# DSP_MMU register map
Vendor: Texas Instruments
Peripheral module from a debugger description file (folder omap4430).
Registers are 32-bit, read-only, reset 0x0 unless marked. A register's access mark holds for its fields unless they carry their own. Offsets are as the file gives them; lines under a group give offsets from that group; [hi:lo] are bit positions; {n}, {i} and the like mark numbered series; 'fields as' and 'values as' point back to an identical list; <NAME> marks a mode.

## DSP_MMU
0x00 MMU_REVISION reset not defined — This register contains the IP revision code
  [31:0] REVISION — IP Revision
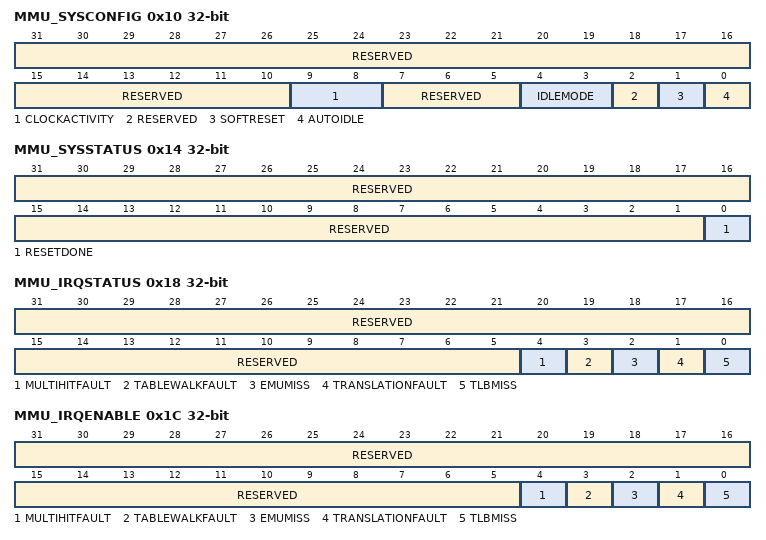
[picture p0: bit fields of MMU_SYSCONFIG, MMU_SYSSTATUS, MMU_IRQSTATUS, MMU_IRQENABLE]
0x10 MMU_SYSCONFIG access per field — This register controls the various parameters of the L3 interconnect interface
  [31:10] RESERVED ro — Write 0's for future compatibility Reads returns 0
  [9:8] CLOCKACTIVITY ro — Clock activity during wake-up mode 00 Functional and Interconnect clocks can be switched off
  [7:5] RESERVED ro — Write 0's for future compatibility Reads returns 0
  [4:3] IDLEMODE rw
    0=Force-idle. An idle request is acknowledged unconditionally; 1=No-idle. An idle request is never acknowledged; 2=Smart-idle. Acknowledgement to an idle request is given based on the internal activity of the module; 3=reserved do not use
  [2] RESERVED ro — Write 0's for future compatibility Reads returns 0
  [1] SOFTRESET rw — Software reset. This bit is automatically reset by the hardware. During reads, it always return 0
    0=SOFTRESET_0_r (always return 0); 0=SOFTRESET_0_w (no functional effect); 1=SOFTRESET_1_w (The module is reset); 1=SOFTRESET_1_r (never happens)
  [0] AUTOIDLE rw — Internal interconnect clock gating strategy
    0=interconnect clock is free-running; 1=Automatic interconnect clock gating strategy is applied, based on the interconnect interface activity
0x14 MMU_SYSSTATUS (reset mask 0xFFFFFFFE) — This register provides status information about the module, excluding the interrupt status information
  [31:1] RESERVED — Reads returns 0
  [0] RESETDONE — Internal reset monitoring
    0=RESETDONE_0_r (Internal module reset in on-going); 1=RESETDONE_1_r (Reset completed)
0x18 MMU_IRQSTATUS access not given — This interrupt status register regroups all the status of the module internal events that can generate an interrupt.
  [31:5] RESERVED ro — Write 0's for future compatibility read returns 0
  [4] MULTIHITFAULT — Error due to multiple matches in the TLB (access RW W1toClr)
    0=MULTIHITFAULT_0_r (MultiHitFault false); 0=MULTIHITFAULT_0_w (MultiHitFault status bit unchanged); 1=MULTIHITFAULT_1_w (MultiHitFault status bit is reset); 1=MULTIHITFAULT_1_r (MultiHitFault is true ('pending'))
  [3] TABLEWALKFAULT — Error response received during a Table Walk (access RW W1toClr)
    0=TABLEWALKFAULT_0_r (TableWalkFault false); 0=TABLEWALKFAULT_0_w (TableWalkFault status bit unchanged); 1=TABLEWALKFAULT_1_w (TableWalkFault status bit is reset); 1=TABLEWALKFAULT_1_r (TableWalkFault is true ('pending'))
  [2] EMUMISS — Unrecoverable TLB miss during debug (hardware TWL disabled) (access RW W1toClr)
    0=EMUMISS_0_r (EMUMiss false); 0=EMUMISS_0_w (EMUMiss status bit unchanged); 1=EMUMISS_1_w (EMUMiss status bit is reset); 1=EMUMISS_1_r (EMUMiss is true ('pending'))
  [1] TRANSLATIONFAULT — Invalid descriptor in translation tables (translation fault) (access RW W1toClr)
    0=TRANSLATIONFAULT_0_r (TranslationFault false); 0=TRANSLATIONFAULT_0_w (TranslationFault status bit unchanged); 1=TRANSLATIONFAULT_1_w (TranslationFault status bit is reset); 1=TRANSLATIONFAULT_1_r (TranslationFault is true ('pending'))
  [0] TLBMISS — Unrecoverable TLB miss (hardware TWL disabled) (access RW W1toClr)
    0=TLBMISS_0_r (TLBMiss false); 0=TLBMISS_0_w (TLBMiss status bit unchanged); 1=TLBMISS_1_w (TLBMiss status bit is reset); 1=TLBMISS_1_r (TLBMiss is true ('pending'))
0x1C MMU_IRQENABLE access per field — The interrupt enable register allows to mask/unmask the module internal sources of interrupt, on a event-by-event basis.
  [31:5] RESERVED ro — Write 0's for future compatibility Read returns 0
  [4] MULTIHITFAULT rw — Error due to multiple matches in the TLB
    0=MultiHitFault is masked; 1=MultiHitFault event generates an interrupt if occurs
  [3] TABLEWALKFAULT rw — Error response received during a Table Walk
    0=TableWalkFault is masked; 1=TableWalkFault event generates an interrupt if occurs
  [2] EMUMISS rw — Unrecoverable TLB miss during debug (hardware TWL disabled)
    0=EMUMiss interrupt is masked; 1=EMUMiss event generates an interrupt when it occurs
  [1] TRANSLATIONFAULT rw — Invalid descriptor in translation tables (translation fault)
    0=TranslationFault is masked; 1=TranslationFault event generates an interrupt if occurs
  [0] TLBMISS rw — Unrecoverable TLB miss (hardware TWL disabled)
    0=TLBMiss interrupt is masked; 1=TLBMiss event generates an interrupt when if occurs
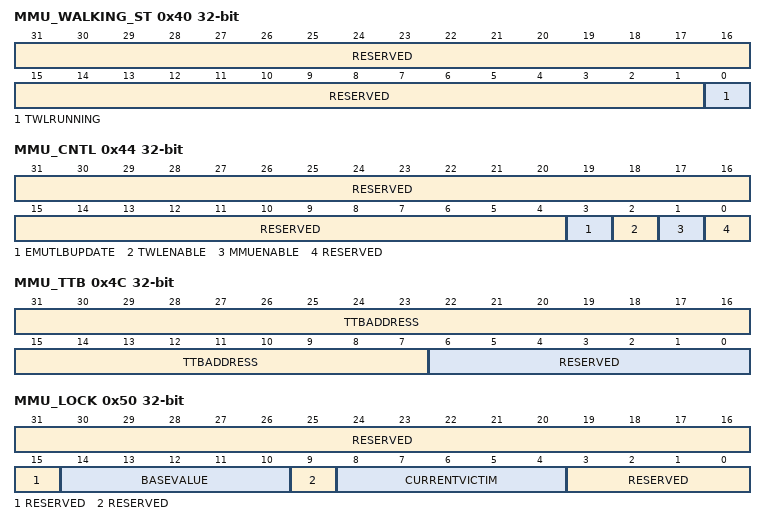
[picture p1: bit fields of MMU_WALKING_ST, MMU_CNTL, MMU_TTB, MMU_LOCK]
0x40 MMU_WALKING_ST — This register provides status information about the table walking logic
  [31:1] RESERVED — Reads return 0
  [0] TWLRUNNING — Table Walking Logic is running
    0=TWLRUNNING_0_r (TWL Completed); 1=TWLRUNNING_1_r
0x44 MMU_CNTL access per field — This register programs the MMU features
  [31:4] RESERVED ro — Write 0's for future compatibility Reads return 0
  [3] EMUTLBUPDATE rw — Enable TLB update on emulator table walk
    0=Emulator TLB update disabled; 1=Emulator TLB update enabled
  [2] TWLENABLE rw — Table Walking Logic enable
    0=TWL disabled; 1=TWL enabled
  [1] MMUENABLE rw
    0=MMU disabled; 1=MMU enabled
  [0] RESERVED ro — Write 0's for future compatibility Reads return 0
0x48 MMU_FAULT_AD — This register contains the virtual address that generated the interrupt
  [31:0] FAULTADDRESS — Virtual address of the access that generated a fault
0x4C MMU_TTB access per field — This register contains the Translation Table Base address
  [31:7] TTBADDRESS rw — Translation Table Base Address
  [6:0] RESERVED ro — Write 0's for future compatibility Reads retiurn 0
0x50 MMU_LOCK access per field — This register locks some of the TLB entries
  [31:15] RESERVED ro — Write 0's for future compatibility Reads return 0
  [14:10] BASEVALUE rw — Locked entries base value
  [9] RESERVED ro — Write 0's for future compatibility Read returns 0
  [8:4] CURRENTVICTIM rw — Current entry to be updated either by the TWL or by the software Write value : TLB entry to be updated by software, Read value : TLB entry that will be updated by table walk logic
  [3:0] RESERVED ro — Write 0's for future compatibility Reads return 0
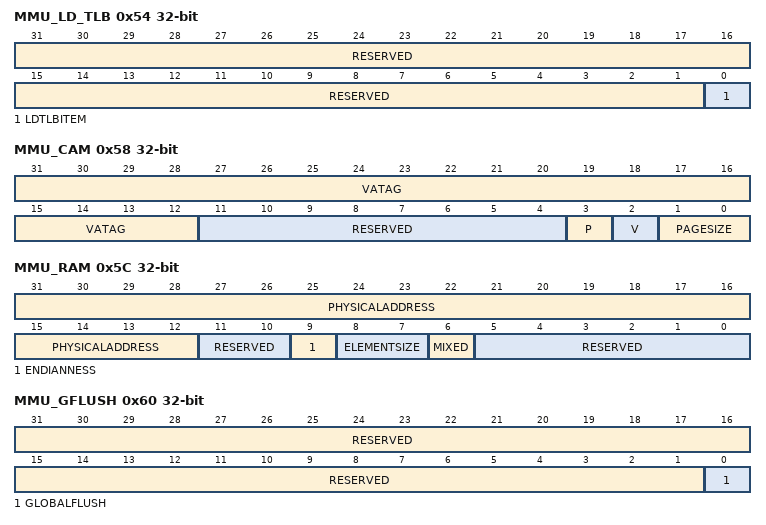
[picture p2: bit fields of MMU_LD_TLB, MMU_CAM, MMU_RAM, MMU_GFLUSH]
0x54 MMU_LD_TLB rw — This register loads a TLB entry (CAM+RAM)
  [31:1] RESERVED — Write 0's for future compatibility Reads return 0
  [0] LDTLBITEM — Write (load) data in the TLB
    0=LDTLBITEM_0_r (always return 0); 0=LDTLBITEM_0_w (no functional effect); 1=LDTLBITEM_1_w (load TLB data); 1=LDTLBITEM_1_r (never happens)
0x58 MMU_CAM access per field — This register holds a CAM entry
  [31:12] VATAG rw — Virtual address tag
  [11:4] RESERVED ro — Write 0's for future compatibility Reads return 0
  [3] P rw — Preserved bit
    0=TLB entry may be flushed; 1=TLB entry is protected against flush
  [2] V rw — Valid bit
    0=TLB entry is invalid; 1=TLB entry is valid
  [1:0] PAGESIZE rw
    0=Section (1MB); 1=Large page (64KB); 2=Small page (4KB); 3=Supersection (16MB)
0x5C MMU_RAM access per field — This register holds a RAM entry
  [31:12] PHYSICALADDRESS rw — Physical address of the page
  [11:10] RESERVED ro — Write 0's for future compatibility Reads return 0
  [9] ENDIANNESS rw — Endianness of the page
    0=Little Endian; 1=Big endian
  [8:7] ELEMENTSIZE rw — Element size of the page (8, 16, 32, no translation)
    0=8-bits; 1=16-bits; 2=32-bits; 3=No translation
  [6] MIXED rw — Mixed page attribute (use CPU element size)
    0=Use TLB element size; 1=Use CPU element size
  [5:0] RESERVED ro — Write 0's for future compatibility Reads return 0
0x60 MMU_GFLUSH rw — This register flushes all the non-protected TLB entries
  [31:1] RESERVED — Write 0's for future compatibility Reads return 0
  [0] GLOBALFLUSH — Flush all the non-protected TLB entries when set
    0=GLOBALFLUSH_0_r (always return 0); 0=GLOBALFLUSH_0_w (no functional effect); 1=GLOBALFLUSH_1_w (flush all the non-protected TLB entries); 1=GLOBALFLUSH_1_r (never happens)
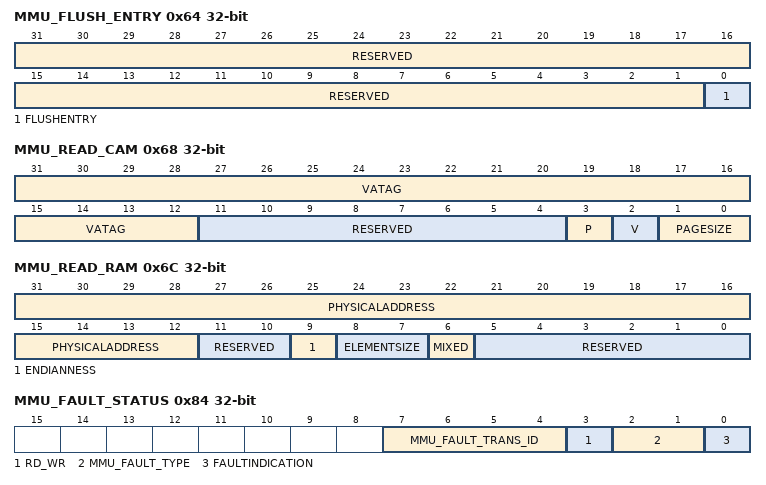
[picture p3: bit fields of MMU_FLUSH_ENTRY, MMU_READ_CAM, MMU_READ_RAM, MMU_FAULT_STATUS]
0x64 MMU_FLUSH_ENTRY rw — This register flushes the entry pointed to by the CAM virtual address
  [31:1] RESERVED — Write 0's for future compatibility Reads return 0
  [0] FLUSHENTRY — Flush the TLB entry pointed by the virtual address (VATag) inMMU_CAM register, even if this entry is set protected
    0=FLUSHENTRY_0_r (always return 0); 0=FLUSHENTRY_0_w (no functional effect); 1=FLUSHENTRY_1_w (flush all the TLB entries specified by the CAM register); 1=FLUSHENTRY_1_r (never happens)
0x68 MMU_READ_CAM — This register reads CAM data from a CAM entry
  [31:12] VATAG — Virtual address tag
  [11:4] RESERVED — Reads return 0
  [3] P — Preserved bit
    0=P_0_r (TLB entry may be flushed); 1=P_1_r (TLB entry is protected against flush)
  [2] V — Valid bit
    0=V_0_r (TLB entry is invalid); 1=V_1_r (TLB entry is valid)
  [1:0] PAGESIZE
    0=PAGESIZE_0_r (Section (1MB)); 1=PAGESIZE_1_r (Large page (64KB)); 2=PAGESIZE_2_r (Small page (4KB)); 3=PAGESIZE_3_r (Supersection (16MB))
0x6C MMU_READ_RAM — This register reads RAM data from a RAM entry
  [31:12] PHYSICALADDRESS — Physical address of the page
  [11:10] RESERVED — Reads return 0
  [9] ENDIANNESS — Endianness of the page
    0=ENDIANNESS_0_r (Little Endian); 1=ENDIANNESS_1_r (Big endian)
  [8:7] ELEMENTSIZE — Element size of the page (8, 16, 32, no translation)
    0=ELEMENTSIZE_0_r (8-bits); 1=ELEMENTSIZE_1_r (16-bits); 2=ELEMENTSIZE_2_r (32-bits); 3=ELEMENTSIZE_3_r (No translation)
  [6] MIXED — Mixed page attribute (use CPU element size)
    0=MIXED_0_r (Use TLB element size); 1=MIXED_1_r (Use CPU element size)
  [5:0] RESERVED — Reads return 0
0x70 MMU_EMU_FAULT_AD — This register contains the last virtual address of a fault caused by the debugger
  [31:0] EMUFAULTADDRESS — Virtual address of the last emulator access that generated a fault
0x80 MMU_FAULT_PC — Capture first fault PC value, controlled by[0] FAULTINDICATION. Notes: The address value is captured at [31:0] EMUFAULTADDRESS. Data-Read-access : corresponding PC. Data-write-access : not perfect accuracy due to Posted-write. All this description is valid only for the DSP MMU. The Cortex-M3 L2 MMU always reads zero from this register.
  [31:0] PC — CPU program counter value where cause MMU fault
0x84 MMU_FAULT_STATUS access not given
  [7:4] MMU_FAULT_TRANS_ID ro — Master ID who cause a faultRead 0x9 to 0xF: reserved (for both Cortex-M3 MMU and DSP MMU) .
    0=MMU_FAULT_TRANS_ID_0_r (posted writes out of shared cache for Cortex-M3 MMU / eDMA read port 1 for DSP MMU); 1=MMU_FAULT_TRANS_ID_1_r (Cortex-M3 video and display control processor I/D bus access for Cortex-M3 MMU / eDMA read port 2 for DSP MMU); 2=MMU_FAULT_TRANS_ID_2_r (Cortex-M3 video and display control processor S bus access for Cortex-M3 MMU / eDMA write port 1 for DSP MMU); 3=MMU_FAULT_TRANS_ID_3_r (Cortex-M3 SIMCOP control processor I/D bus access for Cortex-M3 MMU / eDMA write port 2 for DSP MMU); 4=MMU_FAULT_TRANS_ID_4_r (Cortex-M3 SIMCOP control processor S bus access for Cortex-M3 MMU / shared cache Evictions/stores/Non-cacheable for DSP MMU); 5=MMU_FAULT_TRANS_ID_5_r (reserved for Cortex-M3 MMU / shared cache request for Program/Data for DSP MMU); 6=MMU_FAULT_TRANS_ID_6_r (reserved for Cortex-M3 MMU / shared cache request for DMA for DSP MMU); 7=MMU_FAULT_TRANS_ID_7_r (reserved (for both Cortex-M3 MMU and DSP MMU)); 8=MMU_FAULT_TRANS_ID_8_r (MMU hardware table walk (for both Cortex-M3 MMU and DSP MMU))
  [3] RD_WR ro — indicates read or write
  [2:1] MMU_FAULT_TYPE ro — MReq Type[1:0]
    2=MMU_FAULT_TYPE_2_r (reserved for Cortex-M3 MMU / DMA address for DSP MMU); 1=MMU_FAULT_TYPE_1_r (Fetch address); 0=MMU_FAULT_TYPE_0_r (Data Load/Store)
  [0] FAULTINDICATION — indicates a MMU fault (access RW W1toClr)
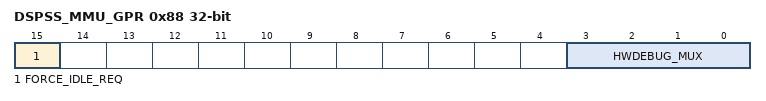
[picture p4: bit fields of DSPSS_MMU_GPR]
0x88 DSPSS_MMU_GPR access per field — This register controls the DSP MMU hardware debug output multiplexer. It also controls force-idle request generation. For more information about the use of this register, see, Control Module.
  [15] FORCE_IDLE_REQ rw — Force-idle request to see existence of pending bus request. This bit must be used only for debug purposes, not in functional mode.
  [3:0] HWDEBUG_MUX rw — Control HWDEBUG output MUX
